AUTOSAR XML (schema 4-3-1)
package /Components
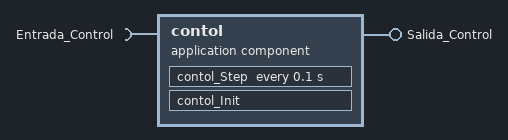
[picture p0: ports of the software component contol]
  application sw component type contol
    require port Entrada_Control: nonqueued-receiver-com-spec{data-element=Entrada_Control, init-value=0}, required-interface=Entrada_Control
    provide port Salida_Control: nonqueued-sender-com-spec{data-element=Salida_Control, init-value=0}, provided-interface=Salida_Control
    behavior contol_IB: handle-termination-and-restart=NO-SUPPORT
      timing event Event_contol_Step: start-on-event=contol_Step, period=0.1
      runnable contol_Init
      runnable contol_Step
        data-read-access:
          access IN_Entrada_Control_Entrada_Control: accessed-variable=Entrada_Control.Entrada_Control
        data-write-access:
          access OUT_Salida_Control_Salida_Control: accessed-variable=Salida_Control.Salida_Control
